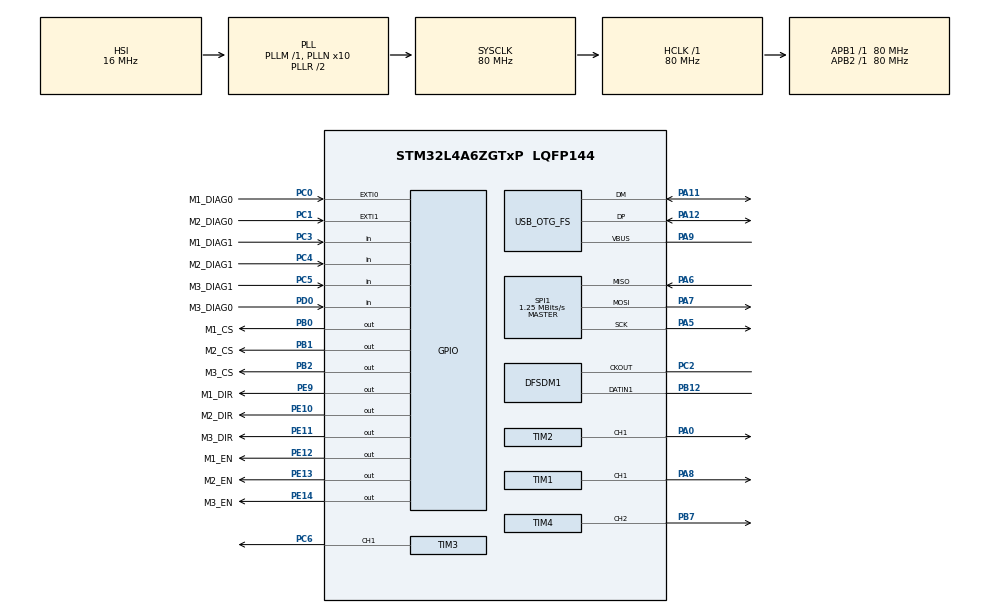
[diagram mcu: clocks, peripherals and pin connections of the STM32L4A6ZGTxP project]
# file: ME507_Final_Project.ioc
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DFSDM1.Divider=80
DFSDM1.DmaMode_reg_FIL0=ENABLE
DFSDM1.FastMode_reg_FIL0=ENABLE
DFSDM1.FilterOrder_CH1=DFSDM_CHANNEL_SINC3_ORDER
DFSDM1.Filter_regChannel_FIL0=DFSDM_CHANNEL_1
DFSDM1.Fosr_FIL0=64
DFSDM1.SincOrder_FIL0=DFSDM_FILTER_SINC3_ORDER
Dma.DFSDM1_FLT0.0.Direction=DMA_PERIPH_TO_MEMORY
Dma.DFSDM1_FLT0.0.Instance=DMA1_Channel4
Dma.DFSDM1_FLT0.0.MemDataAlignment=DMA_MDATAALIGN_WORD
Dma.DFSDM1_FLT0.0.MemInc=DMA_MINC_ENABLE
Dma.DFSDM1_FLT0.0.Mode=DMA_CIRCULAR
Dma.DFSDM1_FLT0.0.PeriphDataAlignment=DMA_PDATAALIGN_WORD
Dma.DFSDM1_FLT0.0.PeriphInc=DMA_PINC_DISABLE
Dma.DFSDM1_FLT0.0.Priority=DMA_PRIORITY_HIGH
Dma.Request0=DFSDM1_FLT0
Mcu.Family=STM32L4
Mcu.Name=STM32L4A6ZGTxP
Mcu.Package=LQFP144
NVIC.DFSDM1_FLT0_IRQn=true\:0\:0\:false\:false\:true\:true\:true\:true
NVIC.DMA1_Channel4_IRQn=true\:0\:0\:false\:false\:true\:false\:true\:true
NVIC.EXTI0_IRQn=true\:0\:0\:false\:false\:true\:true\:true\:true
NVIC.EXTI1_IRQn=true\:0\:0\:false\:false\:true\:true\:true\:true
NVIC.OTG_FS_IRQn=true\:0\:0\:false\:false\:true\:false\:true\:true
NVIC.PriorityGroup=NVIC_PRIORITYGROUP_4
NVIC.TIM1_UP_TIM16_IRQn=true\:0\:0\:false\:false\:true\:true\:true\:true
NVIC.TIM2_IRQn=true\:0\:0\:false\:false\:true\:true\:true\:true
NVIC.TIM3_IRQn=true\:0\:0\:false\:false\:true\:true\:true\:true
PA0.Signal=S_TIM2_CH1
PA11.Mode=Device_Only
PA11.Signal=USB_OTG_FS_DM
PA12.Mode=Device_Only
PA12.Signal=USB_OTG_FS_DP
PA13\ (JTMS/SWDIO).Mode=Trace_Asynchronous_SW
PA13\ (JTMS/SWDIO).Signal=SYS_JTMS-SWDIO
PA14\ (JTCK/SWCLK).Mode=Trace_Asynchronous_SW
PA14\ (JTCK/SWCLK).Signal=SYS_JTCK-SWCLK
PA5.GPIO_PuPd=GPIO_PULLUP
PA5.Mode=Full_Duplex_Master
PA5.Signal=SPI1_SCK
PA6.Mode=Full_Duplex_Master
PA6.Signal=SPI1_MISO
PA7.Mode=Full_Duplex_Master
PA7.Signal=SPI1_MOSI
PA8.Signal=S_TIM1_CH1
PA9.Mode=Activate_VBUS
PA9.Signal=USB_OTG_FS_VBUS
PB0.GPIO_Label=M1_CS
PB0.GPIO_Speed=GPIO_SPEED_FREQ_HIGH
PB0.PinState=GPIO_PIN_SET
PB0.Signal=GPIO_Output
PB1.GPIO_Label=M2_CS
PB1.GPIO_Speed=GPIO_SPEED_FREQ_HIGH
PB1.PinState=GPIO_PIN_SET
PB1.Signal=GPIO_Output
PB12.Signal=S_DATAIN1DFSDM1
PB2.GPIO_Label=M3_CS
PB2.GPIO_Speed=GPIO_SPEED_FREQ_HIGH
PB2.PinState=GPIO_PIN_SET
PB2.Signal=GPIO_Output
PB3\ (JTDO/TRACESWO).Mode=Trace_Asynchronous_SW
PB3\ (JTDO/TRACESWO).Signal=SYS_JTDO-SWO
PB7.Signal=S_TIM4_CH2
PC0.GPIO_Label=M1_DIAG0
PC0.Signal=GPXTI0
PC1.GPIO_Label=M2_DIAG0
PC1.Signal=GPXTI1
PC2.Signal=S_CKOUTDFSDM1
PC3.GPIO_Label=M1_DIAG1
PC3.Signal=GPIO_Input
PC4.GPIO_Label=M2_DIAG1
PC4.Signal=GPIO_Input
PC5.GPIO_Label=M3_DIAG1
PC5.Signal=GPIO_Input
PC6.Signal=S_TIM3_CH1
PD0.GPIO_Label=M3_DIAG0
PD0.Signal=GPIO_Input
PE10.GPIO_Label=M2_DIR
PE10.Signal=GPIO_Output
PE11.GPIO_Label=M3_DIR
PE11.Signal=GPIO_Output
PE12.GPIO_Label=M1_EN
PE12.PinState=GPIO_PIN_SET
PE12.Signal=GPIO_Output
PE13.GPIO_Label=M2_EN
PE13.PinState=GPIO_PIN_SET
PE13.Signal=GPIO_Output
PE14.GPIO_Label=M3_EN
PE14.PinState=GPIO_PIN_SET
PE14.Signal=GPIO_Output
PE9.GPIO_Label=M1_DIR
PE9.Signal=GPIO_Output
PH0-OSC_IN\ (PH0).Mode=HSE-External-Oscillator
PH0-OSC_IN\ (PH0).Signal=RCC_OSC_IN
PH1-OSC_OUT\ (PH1).Mode=HSE-External-Oscillator
PH1-OSC_OUT\ (PH1).Signal=RCC_OSC_OUT
ProjectManager.HeapSize=0x200
ProjectManager.StackSize=0x400
ProjectManager.TargetToolchain=STM32CubeIDE
RCC.ADCFreq_Value=96000000
RCC.AHBFreq_Value=80000000
RCC.APB1Freq_Value=80000000
RCC.APB1TimFreq_Value=80000000
RCC.APB2Freq_Value=80000000
RCC.APB2TimFreq_Value=80000000
RCC.CK48CLockSelection=RCC_USBCLKSOURCE_HSI48
RCC.CortexFreq_Value=80000000
RCC.HCLKFreq_Value=80000000
RCC.HSE_VALUE=8000000
RCC.HSI48_VALUE=48000000
RCC.HSI_VALUE=16000000
RCC.LSE_VALUE=32768
RCC.MSI_VALUE=4000000
RCC.PLLN=10
RCC.PLLSAI1N=12
RCC.PLLSourceVirtual=RCC_PLLSOURCE_HSI
RCC.SYSCLKFreq_VALUE=80000000
RCC.SYSCLKSource=RCC_SYSCLKSOURCE_PLLCLK
RCC.USBFreq_Value=48000000
RCC.VCOOutputFreq_Value=160000000
SH.S_CKOUTDFSDM1.0=DFSDM1_CKOUT,CKOUT
SH.S_CKOUTDFSDM1.1=DFSDM1_CKOUT,PDM_SPI_input_from_ch1_and_internal_clock
SH.S_DATAIN1DFSDM1.0=DFSDM1_DATIN1,PDM_SPI_input_from_ch1_and_internal_clock
SH.S_TIM1_CH1.0=TIM1_CH1,PWM Generation1 CH1
SH.S_TIM2_CH1.0=TIM2_CH1,PWM Generation1 CH1
SH.S_TIM3_CH1.0=TIM3_CH1,PWM Generation1 CH1
SH.S_TIM4_CH2.0=TIM4_CH2,PWM Generation2 CH2
SPI1.BaudRatePrescaler=SPI_BAUDRATEPRESCALER_64
SPI1.CLKPhase=SPI_PHASE_2EDGE
SPI1.CLKPolarity=SPI_POLARITY_HIGH
SPI1.CalculateBaudRate=1.25 MBits/s
SPI1.DataSize=SPI_DATASIZE_8BIT
SPI1.Direction=SPI_DIRECTION_2LINES
SPI1.Mode=SPI_MODE_MASTER
SPI1.VirtualType=VM_MASTER
TIM1.AutoReloadPreload=TIM_AUTORELOAD_PRELOAD_ENABLE
TIM1.Channel-PWM\ Generation1\ CH1=TIM_CHANNEL_1
TIM1.OCFastMode_PWM-PWM\ Generation1\ CH1=TIM_OCFAST_DISABLE
TIM1.Period=999
TIM1.Prescaler=79
TIM1.Pulse-PWM\ Generation1\ CH1=500
TIM2.AutoReloadPreload=TIM_AUTORELOAD_PRELOAD_ENABLE
TIM2.Channel-PWM\ Generation1\ CH1=TIM_CHANNEL_1
TIM2.OCFastMode_PWM-PWM\ Generation1\ CH1=TIM_OCFAST_DISABLE
TIM2.Period=9999
TIM2.Prescaler=79
TIM2.Pulse-PWM\ Generation1\ CH1=500
TIM3.AutoReloadPreload=TIM_AUTORELOAD_PRELOAD_ENABLE
TIM3.Channel-PWM\ Generation1\ CH1=TIM_CHANNEL_1
TIM3.Period=999
TIM3.Prescaler=79
TIM3.Pulse-PWM\ Generation1\ CH1=500
TIM4.AutoReloadPreload=TIM_AUTORELOAD_PRELOAD_ENABLE
TIM4.Channel-PWM\ Generation2\ CH2=TIM_CHANNEL_2
TIM4.Period=9999
TIM4.Prescaler=79
TIM4.Pulse-PWM\ Generation2\ CH2=5000
USB_DEVICE.CLASS_NAME_FS=CDC
USB_DEVICE.VirtualMode=Cdc
USB_DEVICE.VirtualModeFS=Cdc_FS
USB_OTG_FS.VirtualMode=Device_Only
VP_RCC_USB.Mode=CRS SYNC Source USB
VP_TIM1_VS_ClockSourceINT.Mode=Internal
VP_TIM2_VS_ClockSourceINT.Mode=Internal
VP_TIM3_VS_ClockSourceINT.Mode=Internal
VP_TIM4_VS_ClockSourceINT.Mode=Internal
VP_USB_DEVICE_VS_USB_DEVICE_CDC_FS.Mode=CDC_FS
board=custom

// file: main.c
/* USER CODE BEGIN Header */
/**
  * @file           : main.c
  * @brief          : Voice & vision controlled 3-DoF arm — command loop and
  *                   peripheral init. Receives ASCII pick commands over USB CDC,
  *                   runs inverse kinematics, and drives the steppers + gripper.
  */
/* USER CODE END Header */
#include "main.h"
#include "usb_device.h"

/* USER CODE BEGIN Includes */
#include "arm_control.h"
#include "usbd_cdc_if.h"    /* for CDC_Transmit_FS */
#include <stdio.h>
#include <string.h>

/* USER CODE END Includes */

DFSDM_Filter_HandleTypeDef hdfsdm1_filter0;
DFSDM_Channel_HandleTypeDef hdfsdm1_channel1;
DMA_HandleTypeDef hdma_dfsdm1_flt0;

SPI_HandleTypeDef hspi1;

TIM_HandleTypeDef htim1;
TIM_HandleTypeDef htim2;
TIM_HandleTypeDef htim3;
TIM_HandleTypeDef htim4;

/* USER CODE BEGIN PV */
volatile uint8_t cmd_ready = 0;   /**< Set by the USB CDC RX callback when a full command line is buffered. */
volatile char    cmd_buf[64];     /**< Latest received ASCII command line. */
/* USER CODE END PV */

void SystemClock_Config(void);
static void MX_GPIO_Init(void);
static void MX_DMA_Init(void);
static void MX_DFSDM1_Init(void);
static void MX_SPI1_Init(void);
static void MX_TIM1_Init(void);
static void MX_TIM2_Init(void);
static void MX_TIM3_Init(void);
static void MX_TIM4_Init(void);

int main(void)
{

  /* MCU Configuration--------------------------------------------------------*/

  /* Reset of all peripherals, Initializes the Flash interface and the Systick. */
  HAL_Init();

  /* Configure the system clock */
  SystemClock_Config();

  /* Initialize all configured peripherals */
  MX_GPIO_Init();
  MX_DMA_Init();
  MX_DFSDM1_Init();
  MX_SPI1_Init();
  MX_TIM1_Init();
  MX_TIM2_Init();
  MX_TIM3_Init();
  MX_TIM4_Init();
  MX_USB_DEVICE_Init();
  /* USER CODE BEGIN 2 */
    arm_init();
    gripper_init();

    uint8_t  drv_ok = arm_drivers_init();
    uint32_t ioin0  = arm_dbg_ioin(0);
    (void)drv_ok; (void)ioin0;     /* step PAST this line, THEN read both */                      /* break here first: bit 0 must be set, else motor 1 isn't enabled */
//    float fx, fy, fz;
//    arm_fk(0.0f, 1.5707963f, -1.5707963f, &fx, &fy, &fz);   /* +pi/2, -pi/2 */
//    (void)fx; (void)fy; (void)fz;   /* expect fx≈245, fy≈0, fz≈315 <- home position */

      /* test ONE joint, small move, watch which way it goes */
//      arm_test_spin(2, +1, 800, 400.0f);   /* shoulder: +1 should LIFT the upper arm */
//    	arm_move_to(0, 245, 315, 1);
//    arm_move_to(300, 0, 200, 1);
//      while (arm_is_moving()) { }
  /* USER CODE END 2 */

  /* Infinite loop */
  /* USER CODE BEGIN WHILE */
  /**
   * @brief Main command loop.
   *
   * Polls ::cmd_ready and dispatches one ASCII command per line:
   *   - "M,<color>,<x>,<y>,<z>" : solve IK, move to (x,y,z), close gripper on arrival
   *   - "GRIP,OPEN" / "GRIP,CLOSE" : actuate the gripper
   *   - "WHERE" : reply "POS,x,y,z" from forward kinematics
   * Replies "DONE" on success or "ERR" on an unreachable target / parse failure.
   */
      while (1)
      {
    	  if (cmd_ready) {
    	      cmd_ready = 0;

    	      if (strncmp((char*)cmd_buf, "GRIP,OPEN", 9) == 0) {
    	          gripper_open();
    	          HAL_Delay(500);
    	          CDC_Transmit_FS((uint8_t*)"DONE\n", 5);
    	      }
    	      else if (strncmp((char*)cmd_buf, "GRIP,CLOSE", 10) == 0) {
    	          gripper_close();
    	          HAL_Delay(500);
    	          CDC_Transmit_FS((uint8_t*)"DONE\n", 5);
    	      }
    	      else if (strncmp((char*)cmd_buf, "WHERE", 5) == 0) {
    	          float cx, cy, cz;
    	          arm_get_xyz(&cx, &cy, &cz);
    	          char out[48];
    	          int len = snprintf(out, sizeof(out), "POS,%.1f,%.1f,%.1f\n", cx, cy, cz);
    	          CDC_Transmit_FS((uint8_t*)out, len);
    	      }
    	      else {
    	          char color[16];
    	          float x, y, z;
    	          int n = sscanf((char*)cmd_buf, "M,%15[^,],%f,%f,%f", color, &x, &y, &z);
    	          if (n == 4) {
    	              if (!arm_is_moving() && arm_move_to(x, y, z, 1)) {
    	                  while (arm_is_moving()) { }
    	                  HAL_Delay(300);          /* settle */
    	                  gripper_close();         /* grab on arrival */
    	                  HAL_Delay(500);
    	                  CDC_Transmit_FS((uint8_t*)"DONE\n", 5);
    	              } else {
    	                  CDC_Transmit_FS((uint8_t*)"ERR\n", 4);
    	              }
    	          } else {
    	              CDC_Transmit_FS((uint8_t*)"ERR\n", 4);
    	          }
    	      }
    	  }
      }
  /* USER CODE END 3 */
}

void SystemClock_Config(void)
{
  RCC_OscInitTypeDef RCC_OscInitStruct = {0};
  RCC_ClkInitTypeDef RCC_ClkInitStruct = {0};
  RCC_CRSInitTypeDef RCC_CRSInitStruct = {0};

  /** Configure the main internal regulator output voltage
  */
  if (HAL_PWREx_ControlVoltageScaling(PWR_REGULATOR_VOLTAGE_SCALE1) != HAL_OK)
  {
    Error_Handler();
  }

  /** Initializes the RCC Oscillators according to the specified parameters
  * in the RCC_OscInitTypeDef structure.
  */
  RCC_OscInitStruct.OscillatorType = RCC_OSCILLATORTYPE_HSI48|RCC_OSCILLATORTYPE_HSI;
  RCC_OscInitStruct.HSIState = RCC_HSI_ON;
  RCC_OscInitStruct.HSI48State = RCC_HSI48_ON;
  RCC_OscInitStruct.HSICalibrationValue = RCC_HSICALIBRATION_DEFAULT;
  RCC_OscInitStruct.PLL.PLLState = RCC_PLL_ON;
  RCC_OscInitStruct.PLL.PLLSource = RCC_PLLSOURCE_HSI;
  RCC_OscInitStruct.PLL.PLLM = 1;
  RCC_OscInitStruct.PLL.PLLN = 10;
  RCC_OscInitStruct.PLL.PLLP = RCC_PLLP_DIV2;
  RCC_OscInitStruct.PLL.PLLQ = RCC_PLLQ_DIV2;
  RCC_OscInitStruct.PLL.PLLR = RCC_PLLR_DIV2;
  if (HAL_RCC_OscConfig(&RCC_OscInitStruct) != HAL_OK)
  {
    Error_Handler();
  }

  /** Initializes the CPU, AHB and APB buses clocks
  */
  RCC_ClkInitStruct.ClockType = RCC_CLOCKTYPE_HCLK|RCC_CLOCKTYPE_SYSCLK
                              |RCC_CLOCKTYPE_PCLK1|RCC_CLOCKTYPE_PCLK2;
  RCC_ClkInitStruct.SYSCLKSource = RCC_SYSCLKSOURCE_PLLCLK;
  RCC_ClkInitStruct.AHBCLKDivider = RCC_SYSCLK_DIV1;
  RCC_ClkInitStruct.APB1CLKDivider = RCC_HCLK_DIV1;
  RCC_ClkInitStruct.APB2CLKDivider = RCC_HCLK_DIV1;

  if (HAL_RCC_ClockConfig(&RCC_ClkInitStruct, FLASH_LATENCY_4) != HAL_OK)
  {
    Error_Handler();
  }

  /** Enable the SYSCFG APB clock
  */
  __HAL_RCC_CRS_CLK_ENABLE();

  /** Configures CRS
  */
  RCC_CRSInitStruct.Prescaler = RCC_CRS_SYNC_DIV1;
  RCC_CRSInitStruct.Source = RCC_CRS_SYNC_SOURCE_USB;
  RCC_CRSInitStruct.Polarity = RCC_CRS_SYNC_POLARITY_RISING;
  RCC_CRSInitStruct.ReloadValue = __HAL_RCC_CRS_RELOADVALUE_CALCULATE(48000000,1000);
  RCC_CRSInitStruct.ErrorLimitValue = 34;
  RCC_CRSInitStruct.HSI48CalibrationValue = 32;

  HAL_RCCEx_CRSConfig(&RCC_CRSInitStruct);
}

static void MX_DFSDM1_Init(void)
{

  hdfsdm1_filter0.Instance = DFSDM1_Filter0;
  hdfsdm1_filter0.Init.RegularParam.Trigger = DFSDM_FILTER_SW_TRIGGER;
  hdfsdm1_filter0.Init.RegularParam.FastMode = ENABLE;
  hdfsdm1_filter0.Init.RegularParam.DmaMode = ENABLE;
  hdfsdm1_filter0.Init.FilterParam.SincOrder = DFSDM_FILTER_SINC3_ORDER;
  hdfsdm1_filter0.Init.FilterParam.Oversampling = 64;
  hdfsdm1_filter0.Init.FilterParam.IntOversampling = 1;
  if (HAL_DFSDM_FilterInit(&hdfsdm1_filter0) != HAL_OK)
  {
    Error_Handler();
  }
  hdfsdm1_channel1.Instance = DFSDM1_Channel1;
  hdfsdm1_channel1.Init.OutputClock.Activation = ENABLE;
  hdfsdm1_channel1.Init.OutputClock.Selection = DFSDM_CHANNEL_OUTPUT_CLOCK_SYSTEM;
  hdfsdm1_channel1.Init.OutputClock.Divider = 80;
  hdfsdm1_channel1.Init.Input.Multiplexer = DFSDM_CHANNEL_EXTERNAL_INPUTS;
  hdfsdm1_channel1.Init.Input.DataPacking = DFSDM_CHANNEL_STANDARD_MODE;
  hdfsdm1_channel1.Init.Input.Pins = DFSDM_CHANNEL_SAME_CHANNEL_PINS;
  hdfsdm1_channel1.Init.SerialInterface.Type = DFSDM_CHANNEL_SPI_RISING;
  hdfsdm1_channel1.Init.SerialInterface.SpiClock = DFSDM_CHANNEL_SPI_CLOCK_INTERNAL;
  hdfsdm1_channel1.Init.Awd.FilterOrder = DFSDM_CHANNEL_SINC3_ORDER;
  hdfsdm1_channel1.Init.Awd.Oversampling = 1;
  hdfsdm1_channel1.Init.Offset = 0;
  hdfsdm1_channel1.Init.RightBitShift = 0x00;
  if (HAL_DFSDM_ChannelInit(&hdfsdm1_channel1) != HAL_OK)
  {
    Error_Handler();
  }
  if (HAL_DFSDM_FilterConfigRegChannel(&hdfsdm1_filter0, DFSDM_CHANNEL_1, DFSDM_CONTINUOUS_CONV_ON) != HAL_OK)
  {
    Error_Handler();
  }

}

static void MX_SPI1_Init(void)
{

  /* SPI1 parameter configuration*/
  hspi1.Instance = SPI1;
  hspi1.Init.Mode = SPI_MODE_MASTER;
  hspi1.Init.Direction = SPI_DIRECTION_2LINES;
  hspi1.Init.DataSize = SPI_DATASIZE_8BIT;
  hspi1.Init.CLKPolarity = SPI_POLARITY_HIGH;
  hspi1.Init.CLKPhase = SPI_PHASE_2EDGE;
  hspi1.Init.NSS = SPI_NSS_SOFT;
  hspi1.Init.BaudRatePrescaler = SPI_BAUDRATEPRESCALER_64;
  hspi1.Init.FirstBit = SPI_FIRSTBIT_MSB;
  hspi1.Init.TIMode = SPI_TIMODE_DISABLE;
  hspi1.Init.CRCCalculation = SPI_CRCCALCULATION_DISABLE;
  hspi1.Init.CRCPolynomial = 7;
  hspi1.Init.CRCLength = SPI_CRC_LENGTH_DATASIZE;
  hspi1.Init.NSSPMode = SPI_NSS_PULSE_DISABLE;
  if (HAL_SPI_Init(&hspi1) != HAL_OK)
  {
    Error_Handler();
  }
  /* USER CODE BEGIN SPI1_Init 2 */
  __HAL_SPI_ENABLE(&hspi1);   /* SCK parks at idle-high before any CS toggling */
  /* USER CODE END SPI1_Init 2 */

}

static void MX_TIM1_Init(void)
{

  TIM_ClockConfigTypeDef sClockSourceConfig = {0};
  TIM_MasterConfigTypeDef sMasterConfig = {0};
  TIM_OC_InitTypeDef sConfigOC = {0};
  TIM_BreakDeadTimeConfigTypeDef sBreakDeadTimeConfig = {0};

  htim1.Instance = TIM1;
  htim1.Init.Prescaler = 79;
  htim1.Init.CounterMode = TIM_COUNTERMODE_UP;
  htim1.Init.Period = 999;
  htim1.Init.ClockDivision = TIM_CLOCKDIVISION_DIV1;
  htim1.Init.RepetitionCounter = 0;
  htim1.Init.AutoReloadPreload = TIM_AUTORELOAD_PRELOAD_ENABLE;
  if (HAL_TIM_Base_Init(&htim1) != HAL_OK)
  {
    Error_Handler();
  }
  sClockSourceConfig.ClockSource = TIM_CLOCKSOURCE_INTERNAL;
  if (HAL_TIM_ConfigClockSource(&htim1, &sClockSourceConfig) != HAL_OK)
  {
    Error_Handler();
  }
  if (HAL_TIM_PWM_Init(&htim1) != HAL_OK)
  {
    Error_Handler();
  }
  sMasterConfig.MasterOutputTrigger = TIM_TRGO_RESET;
  sMasterConfig.MasterOutputTrigger2 = TIM_TRGO2_RESET;
  sMasterConfig.MasterSlaveMode = TIM_MASTERSLAVEMODE_DISABLE;
  if (HAL_TIMEx_MasterConfigSynchronization(&htim1, &sMasterConfig) != HAL_OK)
  {
    Error_Handler();
  }
  sConfigOC.OCMode = TIM_OCMODE_PWM1;
  sConfigOC.Pulse = 500;
  sConfigOC.OCPolarity = TIM_OCPOLARITY_HIGH;
  sConfigOC.OCNPolarity = TIM_OCNPOLARITY_HIGH;
  sConfigOC.OCFastMode = TIM_OCFAST_DISABLE;
  sConfigOC.OCIdleState = TIM_OCIDLESTATE_RESET;
  sConfigOC.OCNIdleState = TIM_OCNIDLESTATE_RESET;
  if (HAL_TIM_PWM_ConfigChannel(&htim1, &sConfigOC, TIM_CHANNEL_1) != HAL_OK)
  {
    Error_Handler();
  }
  sBreakDeadTimeConfig.OffStateRunMode = TIM_OSSR_DISABLE;
  sBreakDeadTimeConfig.OffStateIDLEMode = TIM_OSSI_DISABLE;
  sBreakDeadTimeConfig.LockLevel = TIM_LOCKLEVEL_OFF;
  sBreakDeadTimeConfig.DeadTime = 0;
  sBreakDeadTimeConfig.BreakState = TIM_BREAK_DISABLE;
  sBreakDeadTimeConfig.BreakPolarity = TIM_BREAKPOLARITY_HIGH;
  sBreakDeadTimeConfig.BreakFilter = 0;
  sBreakDeadTimeConfig.Break2State = TIM_BREAK2_DISABLE;
  sBreakDeadTimeConfig.Break2Polarity = TIM_BREAK2POLARITY_HIGH;
  sBreakDeadTimeConfig.Break2Filter = 0;
  sBreakDeadTimeConfig.AutomaticOutput = TIM_AUTOMATICOUTPUT_DISABLE;
  if (HAL_TIMEx_ConfigBreakDeadTime(&htim1, &sBreakDeadTimeConfig) != HAL_OK)
  {
    Error_Handler();
  }
  HAL_TIM_MspPostInit(&htim1);

}

static void MX_TIM2_Init(void)
{

  TIM_ClockConfigTypeDef sClockSourceConfig = {0};
  TIM_MasterConfigTypeDef sMasterConfig = {0};
  TIM_OC_InitTypeDef sConfigOC = {0};

  htim2.Instance = TIM2;
  htim2.Init.Prescaler = 79;
  htim2.Init.CounterMode = TIM_COUNTERMODE_UP;
  htim2.Init.Period = 9999;
  htim2.Init.ClockDivision = TIM_CLOCKDIVISION_DIV1;
  htim2.Init.AutoReloadPreload = TIM_AUTORELOAD_PRELOAD_ENABLE;
  if (HAL_TIM_Base_Init(&htim2) != HAL_OK)
  {
    Error_Handler();
  }
  sClockSourceConfig.ClockSource = TIM_CLOCKSOURCE_INTERNAL;
  if (HAL_TIM_ConfigClockSource(&htim2, &sClockSourceConfig) != HAL_OK)
  {
    Error_Handler();
  }
  if (HAL_TIM_PWM_Init(&htim2) != HAL_OK)
  {
    Error_Handler();
  }
  sMasterConfig.MasterOutputTrigger = TIM_TRGO_RESET;
  sMasterConfig.MasterSlaveMode = TIM_MASTERSLAVEMODE_DISABLE;
  if (HAL_TIMEx_MasterConfigSynchronization(&htim2, &sMasterConfig) != HAL_OK)
  {
    Error_Handler();
  }
  sConfigOC.OCMode = TIM_OCMODE_PWM1;
  sConfigOC.Pulse = 500;
  sConfigOC.OCPolarity = TIM_OCPOLARITY_HIGH;
  sConfigOC.OCFastMode = TIM_OCFAST_DISABLE;
  if (HAL_TIM_PWM_ConfigChannel(&htim2, &sConfigOC, TIM_CHANNEL_1) != HAL_OK)
  {
    Error_Handler();
  }
  HAL_TIM_MspPostInit(&htim2);

}

static void MX_TIM3_Init(void)
{

  TIM_ClockConfigTypeDef sClockSourceConfig = {0};
  TIM_MasterConfigTypeDef sMasterConfig = {0};
  TIM_OC_InitTypeDef sConfigOC = {0};

  htim3.Instance = TIM3;
  htim3.Init.Prescaler = 79;
  htim3.Init.CounterMode = TIM_COUNTERMODE_UP;
  htim3.Init.Period = 999;
  htim3.Init.ClockDivision = TIM_CLOCKDIVISION_DIV1;
  htim3.Init.AutoReloadPreload = TIM_AUTORELOAD_PRELOAD_ENABLE;
  if (HAL_TIM_Base_Init(&htim3) != HAL_OK)
  {
    Error_Handler();
  }
  sClockSourceConfig.ClockSource = TIM_CLOCKSOURCE_INTERNAL;
  if (HAL_TIM_ConfigClockSource(&htim3, &sClockSourceConfig) != HAL_OK)
  {
    Error_Handler();
  }
  if (HAL_TIM_PWM_Init(&htim3) != HAL_OK)
  {
    Error_Handler();
  }
  sMasterConfig.MasterOutputTrigger = TIM_TRGO_RESET;
  sMasterConfig.MasterSlaveMode = TIM_MASTERSLAVEMODE_DISABLE;
  if (HAL_TIMEx_MasterConfigSynchronization(&htim3, &sMasterConfig) != HAL_OK)
  {
    Error_Handler();
  }
  sConfigOC.OCMode = TIM_OCMODE_PWM1;
  sConfigOC.Pulse = 500;
  sConfigOC.OCPolarity = TIM_OCPOLARITY_HIGH;
  sConfigOC.OCFastMode = TIM_OCFAST_DISABLE;
  if (HAL_TIM_PWM_ConfigChannel(&htim3, &sConfigOC, TIM_CHANNEL_1) != HAL_OK)
  {
    Error_Handler();
  }
  HAL_TIM_MspPostInit(&htim3);

}

static void MX_TIM4_Init(void)
{

  TIM_ClockConfigTypeDef sClockSourceConfig = {0};
  TIM_MasterConfigTypeDef sMasterConfig = {0};
  TIM_OC_InitTypeDef sConfigOC = {0};

  htim4.Instance = TIM4;
  htim4.Init.Prescaler = 79;
  htim4.Init.CounterMode = TIM_COUNTERMODE_UP;
  htim4.Init.Period = 19999;
  htim4.Init.ClockDivision = TIM_CLOCKDIVISION_DIV1;
  htim4.Init.AutoReloadPreload = TIM_AUTORELOAD_PRELOAD_ENABLE;
  if (HAL_TIM_Base_Init(&htim4) != HAL_OK)
  {
    Error_Handler();
  }
  sClockSourceConfig.ClockSource = TIM_CLOCKSOURCE_INTERNAL;
  if (HAL_TIM_ConfigClockSource(&htim4, &sClockSourceConfig) != HAL_OK)
  {
    Error_Handler();
  }
  if (HAL_TIM_PWM_Init(&htim4) != HAL_OK)
  {
    Error_Handler();
  }
  sMasterConfig.MasterOutputTrigger = TIM_TRGO_RESET;
  sMasterConfig.MasterSlaveMode = TIM_MASTERSLAVEMODE_DISABLE;
  if (HAL_TIMEx_MasterConfigSynchronization(&htim4, &sMasterConfig) != HAL_OK)
  {
    Error_Handler();
  }
  sConfigOC.OCMode = TIM_OCMODE_PWM1;
  sConfigOC.Pulse = 5000;
  sConfigOC.OCPolarity = TIM_OCPOLARITY_HIGH;
  sConfigOC.OCFastMode = TIM_OCFAST_DISABLE;
  if (HAL_TIM_PWM_ConfigChannel(&htim4, &sConfigOC, TIM_CHANNEL_2) != HAL_OK)
  {
    Error_Handler();
  }
  HAL_TIM_MspPostInit(&htim4);

}

static void MX_DMA_Init(void)
{

  /* DMA controller clock enable */
  __HAL_RCC_DMA1_CLK_ENABLE();

  /* DMA interrupt init */
  /* DMA1_Channel4_IRQn interrupt configuration */
  HAL_NVIC_SetPriority(DMA1_Channel4_IRQn, 0, 0);
  HAL_NVIC_EnableIRQ(DMA1_Channel4_IRQn);

}

static void MX_GPIO_Init(void)
{
  GPIO_InitTypeDef GPIO_InitStruct = {0};

  /* GPIO Ports Clock Enable */
  __HAL_RCC_GPIOH_CLK_ENABLE();
  __HAL_RCC_GPIOC_CLK_ENABLE();
  __HAL_RCC_GPIOA_CLK_ENABLE();
  __HAL_RCC_GPIOB_CLK_ENABLE();
  __HAL_RCC_GPIOE_CLK_ENABLE();
  __HAL_RCC_GPIOD_CLK_ENABLE();

  /*Configure GPIO pin Output Level */
  HAL_GPIO_WritePin(GPIOB, M1_CS_Pin|M2_CS_Pin|M3_CS_Pin, GPIO_PIN_SET);

  /*Configure GPIO pin Output Level */
  HAL_GPIO_WritePin(GPIOE, M1_DIR_Pin|M2_DIR_Pin|M3_DIR_Pin, GPIO_PIN_RESET);

  /*Configure GPIO pin Output Level */
  HAL_GPIO_WritePin(GPIOE, M1_EN_Pin|M2_EN_Pin|M3_EN_Pin, GPIO_PIN_SET);

  /*Configure GPIO pins : M1_DIAG0_Pin M2_DIAG0_Pin */
  GPIO_InitStruct.Pin = M1_DIAG0_Pin|M2_DIAG0_Pin;
  GPIO_InitStruct.Mode = GPIO_MODE_IT_RISING;
  GPIO_InitStruct.Pull = GPIO_NOPULL;
  HAL_GPIO_Init(GPIOC, &GPIO_InitStruct);

  /*Configure GPIO pins : M1_DIAG1_Pin M2_DIAG1_Pin M3_DIAG1_Pin */
  GPIO_InitStruct.Pin = M1_DIAG1_Pin|M2_DIAG1_Pin|M3_DIAG1_Pin;
  GPIO_InitStruct.Mode = GPIO_MODE_INPUT;
  GPIO_InitStruct.Pull = GPIO_NOPULL;
  HAL_GPIO_Init(GPIOC, &GPIO_InitStruct);

  /*Configure GPIO pins : M1_CS_Pin M2_CS_Pin M3_CS_Pin */
  GPIO_InitStruct.Pin = M1_CS_Pin|M2_CS_Pin|M3_CS_Pin;
  GPIO_InitStruct.Mode = GPIO_MODE_OUTPUT_PP;
  GPIO_InitStruct.Pull = GPIO_NOPULL;
  GPIO_InitStruct.Speed = GPIO_SPEED_FREQ_HIGH;
  HAL_GPIO_Init(GPIOB, &GPIO_InitStruct);

  /*Configure GPIO pins : M1_DIR_Pin M2_DIR_Pin M3_DIR_Pin M1_EN_Pin
                           M2_EN_Pin M3_EN_Pin */
  GPIO_InitStruct.Pin = M1_DIR_Pin|M2_DIR_Pin|M3_DIR_Pin|M1_EN_Pin
                          |M2_EN_Pin|M3_EN_Pin;
  GPIO_InitStruct.Mode = GPIO_MODE_OUTPUT_PP;
  GPIO_InitStruct.Pull = GPIO_NOPULL;
  GPIO_InitStruct.Speed = GPIO_SPEED_FREQ_LOW;
  HAL_GPIO_Init(GPIOE, &GPIO_InitStruct);

  /*Configure GPIO pin : M3_DIAG0_Pin */
  GPIO_InitStruct.Pin = M3_DIAG0_Pin;
  GPIO_InitStruct.Mode = GPIO_MODE_INPUT;
  GPIO_InitStruct.Pull = GPIO_NOPULL;
  HAL_GPIO_Init(M3_DIAG0_GPIO_Port, &GPIO_InitStruct);

  /* EXTI interrupt init*/
  HAL_NVIC_SetPriority(EXTI0_IRQn, 0, 0);
  HAL_NVIC_EnableIRQ(EXTI0_IRQn);

  HAL_NVIC_SetPriority(EXTI1_IRQn, 0, 0);
  HAL_NVIC_EnableIRQ(EXTI1_IRQn);

}

void Error_Handler(void)
{
  __disable_irq();
  while (1)
  {
  }
}
